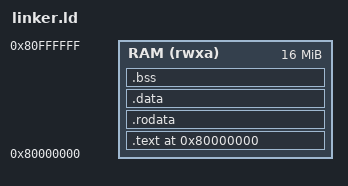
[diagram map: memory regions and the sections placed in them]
OUTPUT_ARCH(riscv)
ENTRY(_start)

MEMORY {
    RAM (rwxa) : ORIGIN = 0x80000000, LENGTH = 16M
}

SECTIONS {
    . = 0x80000000;

    .text : {
        *(.text.init)
        *(.text.trap)
        *(.text .text.*)
    } > RAM

    .rodata : {
        *(.rodata .rodata.*)
        *(.srodata .srodata.*)
    } > RAM

    .data : {
        *(.data .data.*)
        *(.sdata .sdata.*)
    } > RAM

    .bss : {
        _bss_start = .;
        *(.sbss .sbss.*)
        *(.bss .bss.*)
        *(COMMON)
        . = ALIGN(4);
        _bss_end = .;
    } > RAM

    . = ORIGIN(RAM) + LENGTH(RAM);
    _stack_top = .;
}
